# R7KA8T2AD register map
Vendor: Renesas Electronics Corporation; Series: RA8; File version: 1.10.02
CPU: CM85 r0p2, little endian, MPU, FPU, VTOR, 4 interrupt priority bits, 96 interrupts
Registers are 32-bit, read-write, reset 0x0 unless marked. A register's access mark holds for its fields unless they carry their own. Offsets are from the block's base; [hi:lo] are bit positions; {n}, {i} and the like mark numbered series.

## GPT_OPS — Output Phase Switching Controller
Base 0x40323F00
Same registers: GPT_OPS_NS 0x50323F00
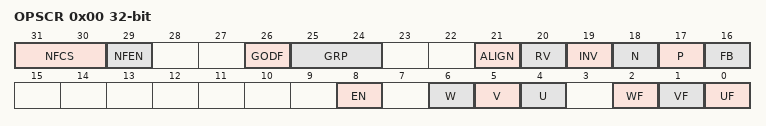
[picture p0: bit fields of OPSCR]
0x00 OPSCR — Output Phase Switching Control Register
  [31:30] NFCS — External Input Noise Filter Clock Selection
    0=GTCLK/1; 1=GTCLK/4; 2=GTCLK/16; 3=GTCLK/64
  [29] NFEN — External Input Noise Filter Enable
    0=Do not use a noise filter on the external input; 1=Use a noise filter on the external input
  [26] GODF — Group Output Disable Function
    0=This bit function is ignored; 1=Group disable clears the OPSCR.EN bit
  [25:24] GRP — Output Disabled Source Selection
  [21] ALIGN — Input Phase Alignment
    0=Input phase aligned to GTCLK; 1=Input phase aligned to the falling edge of PWM
  [20] RV — Output Phase Rotation Direction Reversal Control
    0=Positive rotation; 1=Reverse rotation
  [19] INV — Output Phase Invert Control
    0=Positive logic (active-high) output; 1=Negative logic (active-low) output
  [18] N — Negative-Phase Output (N) Control
    0=Level signal output; 1=PWM signal output
  [17] P — Positive-Phase Output (P) Control
    0=Level signal output; 1=PWM signal output
  [16] FB — External Feedback Signal Enable
    0=Select the external input; 1=Select the soft setting (OPSCR.UF, VF, WF)
  [8] EN — Output Phase Enable
    0=Do not output (Hi-Z external pin); 1=Output
  [6] W ro — Input W-Phase Monitor
  [5] V ro — Input V-Phase Monitor
  [4] U ro — Input U-Phase Monitor
  [2] WF
  [1] VF
  [0] UF

## GPT_GTCLK — General PWM Timer Clock Controller
Base 0x40323F10
Same registers: GPT_GTCLK_NS 0x50323F10
0x00 GTCLKCR — General PWM Timer Clock Control Register
  [0] BPEN — Synchronization Circuit Bypass Enable
    0=In case of using Bus Clock and GPT Core Clock asynchronously; 1=In case of using Bus Clock and GPT Core Clock synchronously

## PDG — PWM Delay Generation Circuit
Base 0x40324000
Same registers: PDG_NS 0x50324000
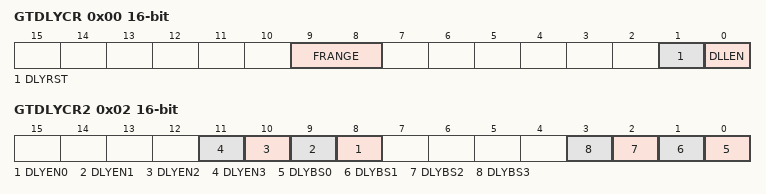
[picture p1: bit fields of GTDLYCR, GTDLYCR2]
0x00 GTDLYCR 16-bit — PWM Output Delay Control Register
  [9:8] FRANGE — GPT core clock Frequency Range
    0=GPT core clock frequency is 80 MHz to 160 MHz; 1=GPT core clock frequency is 155 MHz to 300 MHz; other=Others (Setting prohibited)
  [1] DLYRST — PWM Delay Generation Circuit Reset
    0=Normal operation; 1=Reset
  [0] DLLEN — DLL Operation Enable
    0=DLL operation disabled; 1=DLL operation enabled
0x02 GTDLYCR2 16-bit — PWM Output Delay Control Register 2
  [n+8] DLYEN{n} (n=0..3) — PWM Delay Generation Circuit enable for channel {n}
    0=Delay generation circuit of channel {n} enabled; 1=Delay generation circuit of channel {n} disabled
  [n] DLYBS{n} (n=0..3) — PWM Delay Generation Circuit bypass for channel {n}
    0=Delay generation circuit of channel {n} bypassed; 1=Delay generation circuit of channel {n} not bypassed
{0x18+4i} GTDLYR{i}A (i=0..3) 16-bit — GTIOCnA Rising Output Delay Register
  [6:0] DLY — GTIOCnA Output Rising Edge Delay Setting
{0x1A+4i} GTDLYR{i}B (i=0..3) 16-bit — GTIOCnB Rising Output Delay Register
  [6:0] DLY — GTIOCnB Output Rising Edge Delay Setting
{0x28+4i} GTDLYF{i}A (i=0..3) 16-bit — GTIOCnA Falling Output Delay Register
  [6:0] DLY — GTIOCnA Output Falling Edge Delay Setting
{0x2A+4i} GTDLYF{i}B (i=0..3) 16-bit — GTIOCnB Falling Output Delay Register
  [6:0] DLY — GTIOCnB Output Falling Edge Delay Setting

## ECCMB0
Base 0x4036F200
Same registers: ECCMB1 0x4036F300, ECCMB0_NS 0x5036F200, ECCMB1_NS 0x5036F300
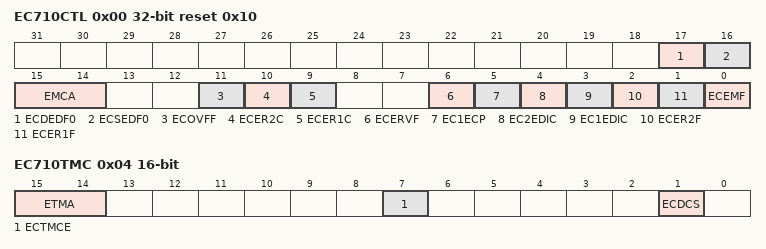
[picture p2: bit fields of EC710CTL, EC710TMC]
0x00 EC710CTL reset 0x10 — ECC Control Register
  [17] ECDEDF0 ro — ECC Dual Bit Error Address Detection Flag
    0=There is no bit error in EC710EAD0 after reset or clearing ECER2F bit; 1=Address captured in EC710EAD0 shows that 2-bit error occurred and captured
  [16] ECSEDF0 ro — ECC Single bit Error Address Detection Flag
    0=There is no bit error in EC710EAD0 after reset or clearing ECER1F bit; 1=Address captured in EC710EAD0 shows that 1-bit error occurred and captured
  [15:14] EMCA — Access Control to ECC Mode Select bit
  [11] ECOVFF ro — ECC Overflow Detection Flag
    0=No effect; 1=ECC overflow detection flag
  [10] ECER2C — 2-bit ECC Error Detection Flag Clear
    0=No effect; 1=Clear 2-bit ECC error detection flag
  [9] ECER1C — Accumulating ECC Error Detection and Correction Flag Clear
    0=No effect; 1=Clear accumulating ECC error detection and correction flag
  [6] ECERVF — ECC Error Judgment Enable Flag
    0=Error judgment disable; 1=Error judgment enable
  [5] EC1ECP — ECC 1-bit Error Correction Permission
    0=At 1-bit error detection, the error correction is executed; 1=At 1-bit error detection, the error correction is not executed
  [4] EC2EDIC — ECC 2-bit Error Detection Interrupt Control
    0=Disable 2-bit error detection interrupt request; 1=Enable 2-bit error detection interrupt request
  [3] EC1EDIC — ECC 1-bit Error Detection Interrupt Control
    0=Disable 1-bit error detection interrupt request; 1=Enable 1-bit error detection interrupt request
  [2] ECER2F ro — 2-bit ECC Error Detection Flag
    0=After clearing this bit, 2-bit error has not occurred; 1=2-bit error has occurred
  [1] ECER1F ro — ECC Error Detection and Correction Flag
    0=After clearing this bit, 1-bit error correction has not occurred; 1=1-bit error has occurred
  [0] ECEMF ro — ECC Error Message Flag
    0=There is no bit error in present RAM output data; 1=There is bit error in present RAM output data
0x04 EC710TMC 16-bit — ECC Test Mode Control Register
  [15:14] ETMA — ECC Test Mode Bit Access Control
  [7] ECTMCE — ECC Test Mode Control Enable
    0=The access to test mode register and bit is disabled; 1=The access to test mode register and bit is enabled
  [1] ECDCS — ECC Decode Input Select
    0=Input lower 32 bits of RAM output data to data area of decode circuit; 1=Input ECEDB31-0 in EC710TED register to data area of decode circuit
0x0C EC710TED — ECC Test Substitute Data Register
  [31:0] ECEDB — ECC Test Substitute Data
0x10 EC710EAD0 ro — ECC Error Address Register
  [9:0] ECEAD — ECC Error Address
